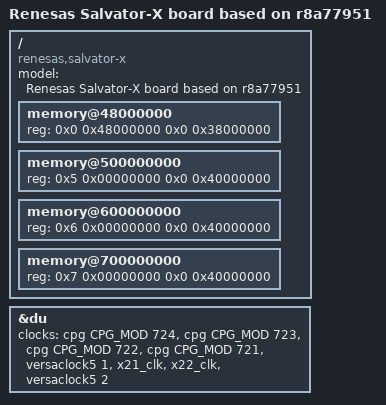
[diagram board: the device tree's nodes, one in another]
// SPDX-License-Identifier: GPL-2.0
/*
 * Device Tree Source for the Salvator-X board with R-Car H3 ES2.0
 *
 * Copyright (C) 2015 Renesas Electronics Corp.
 */

/dts-v1/;
#include "r8a77951.dtsi"
#include "salvator-x.dtsi"

/ {
	model = "Renesas Salvator-X board based on r8a77951";
	compatible = "renesas,salvator-x", "renesas,r8a7795";

	memory@48000000 {
		device_type = "memory";
		/* first 128MB is reserved for secure area. */
		reg = <0x0 0x48000000 0x0 0x38000000>;
	};

	memory@500000000 {
		device_type = "memory";
		reg = <0x5 0x00000000 0x0 0x40000000>;
	};

	memory@600000000 {
		device_type = "memory";
		reg = <0x6 0x00000000 0x0 0x40000000>;
	};

	memory@700000000 {
		device_type = "memory";
		reg = <0x7 0x00000000 0x0 0x40000000>;
	};
};

&du {
	clocks = <&cpg CPG_MOD 724>,
		 <&cpg CPG_MOD 723>,
		 <&cpg CPG_MOD 722>,
		 <&cpg CPG_MOD 721>,
		 <&versaclock5 1>,
		 <&x21_clk>,
		 <&x22_clk>,
		 <&versaclock5 2>;
	clock-names = "du.0", "du.1", "du.2", "du.3",
		      "dclkin.0", "dclkin.1", "dclkin.2", "dclkin.3";
};
